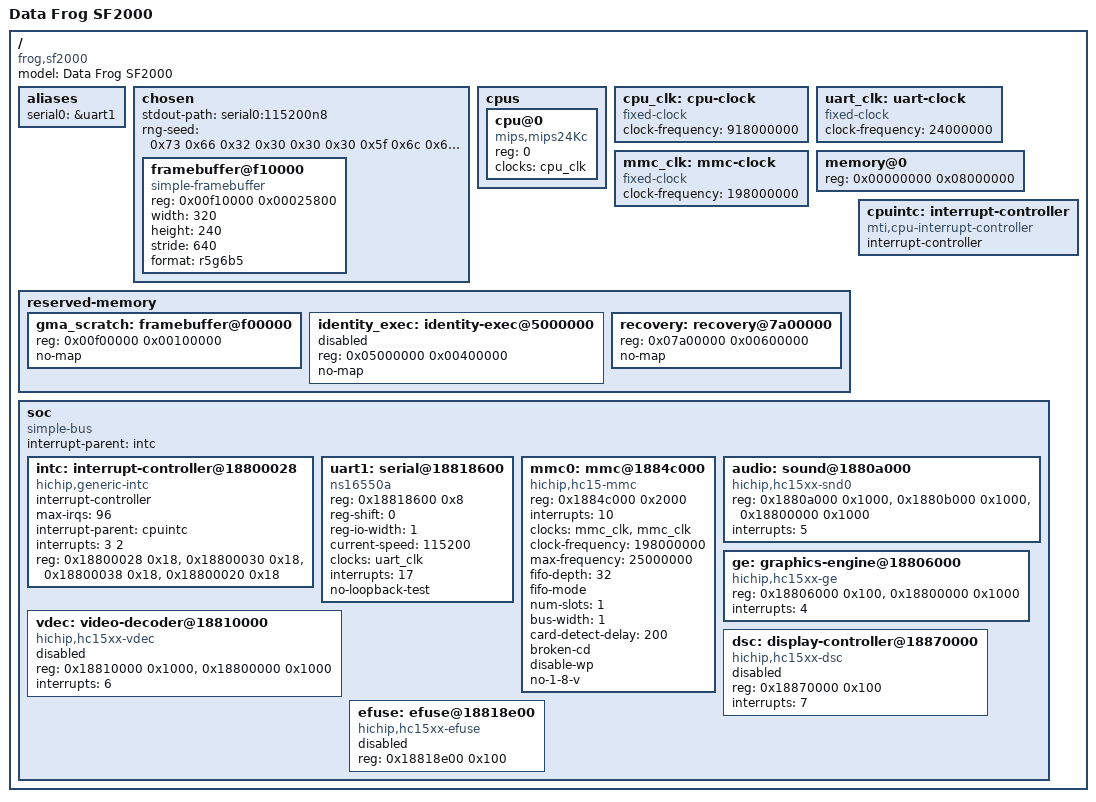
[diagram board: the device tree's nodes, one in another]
// SPDX-License-Identifier: MIT
/dts-v1/;

/ {
	#address-cells = <1>;
	#size-cells = <1>;
	compatible = "frog,sf2000", "hichip,hc15xx";
	model = "Data Frog SF2000";

	aliases {
		serial0 = &uart1;
	};

	chosen {
		#address-cells = <1>;
		#size-cells = <1>;
		ranges;
		stdout-path = "serial0:115200n8";

		rng-seed = /bits/ 8 <
			0x73 0x66 0x32 0x30 0x30 0x30 0x5f 0x6c
			0x69 0x6e 0x75 0x78 0x5f 0x62 0x72 0x69
			0x6e 0x67 0x75 0x70 0x5f 0x73 0x65 0x65
			0x64 0x5f 0x30 0x30 0x30 0x30 0x30 0x31
		>;

		framebuffer@f10000 {
			compatible = "simple-framebuffer";
			reg = <0x00f10000 0x00025800>;
			width = <320>;
			height = <240>;
			stride = <640>;
			format = "r5g6b5";
			status = "okay";
		};
	};

	cpus {
		#address-cells = <1>;
		#size-cells = <0>;

		cpu@0 {
			device_type = "cpu";
			compatible = "mips,mips24Kc", "img,mips";
			reg = <0>;
			clocks = <&cpu_clk>;
		};
	};

	cpu_clk: cpu-clock {
		compatible = "fixed-clock";
		#clock-cells = <0>;
		/*
		 * The ASD loader selects the validated HC1512 digital-PLL
		 * performance profile before entering Linux.  CP0 Count
		 * consequently starts and remains at the 459 MHz half-rate.
		 */
		clock-frequency = <918000000>;
	};

	uart_clk: uart-clock {
		compatible = "fixed-clock";
		#clock-cells = <0>;
		clock-frequency = <24000000>;
	};

	mmc_clk: mmc-clock {
		compatible = "fixed-clock";
		#clock-cells = <0>;
		clock-frequency = <198000000>;
	};

	memory@0 {
		device_type = "memory";
		reg = <0x00000000 0x08000000>;
	};

	reserved-memory {
		#address-cells = <1>;
		#size-cells = <1>;
		ranges;

		gma_scratch: framebuffer@f00000 {
			reg = <0x00f00000 0x00100000>;
			no-map;
		};

		identity_exec: identity-exec@5000000 {
			reg = <0x05000000 0x00400000>;
			no-map;
			status = "disabled";
		};

		recovery: recovery@7a00000 {
			reg = <0x07a00000 0x00600000>;
			no-map;
		};
	};

	cpuintc: interrupt-controller {
		#address-cells = <0>;
		#interrupt-cells = <1>;
		interrupt-controller;
		compatible = "mti,cpu-interrupt-controller";
	};

	soc {
		compatible = "simple-bus";
		#address-cells = <1>;
		#size-cells = <1>;
		ranges;
		interrupt-parent = <&intc>;

		intc: interrupt-controller@18800028 {
			compatible = "hichip,generic-intc";
			interrupt-controller;
			#interrupt-cells = <1>;
			max-irqs = <96>;
			interrupt-parent = <&cpuintc>;
			interrupts = <3 2>;
			reg = <0x18800028 0x18>,
			      <0x18800030 0x18>,
			      <0x18800038 0x18>,
			      <0x18800020 0x18>;
		};

		uart1: serial@18818600 {
			compatible = "ns16550a";
			reg = <0x18818600 0x8>;
			reg-shift = <0>;
			reg-io-width = <1>;
			current-speed = <115200>;
			clocks = <&uart_clk>;
			/* HCRTOS peripherals.ld identifies UART1 as SYSINT 17. */
			interrupts = <17>;
			no-loopback-test;
			status = "okay";
		};

		mmc0: mmc@1884c000 {
			compatible = "hichip,hc15-mmc";
			reg = <0x1884c000 0x2000>;
			interrupts = <10>;
			clocks = <&mmc_clk>, <&mmc_clk>;
			clock-names = "biu", "ciu";
			clock-frequency = <198000000>;
			max-frequency = <25000000>;
			fifo-depth = <32>;
			fifo-mode;
			num-slots = <1>;
			bus-width = <1>;
			card-detect-delay = <200>;
			broken-cd;
			disable-wp;
			no-1-8-v;
			status = "okay";
		};

		audio: sound@1880a000 {
			compatible = "hichip,hc15xx-snd0";
			reg = <0x1880a000 0x1000>,
			      <0x1880b000 0x1000>,
			      <0x18800000 0x1000>;
			interrupts = <5>;
			status = "okay";
		};

		ge: graphics-engine@18806000 {
			compatible = "hichip,hc15xx-ge";
			reg = <0x18806000 0x100>,
			      <0x18800000 0x1000>;
			interrupts = <4>;
			status = "okay";
		};

		vdec: video-decoder@18810000 {
			compatible = "hichip,hc15xx-vdec";
			reg = <0x18810000 0x1000>,
			      <0x18800000 0x1000>;
			reg-names = "vdec", "sys";
			interrupts = <6>;
			status = "disabled";
		};

		dsc: display-controller@18870000 {
			compatible = "hichip,hc15xx-dsc";
			reg = <0x18870000 0x100>;
			interrupts = <7>;
			status = "disabled";
		};

		efuse: efuse@18818e00 {
			compatible = "hichip,hc15xx-efuse";
			reg = <0x18818e00 0x100>;
			status = "disabled";
		};
	};
};
